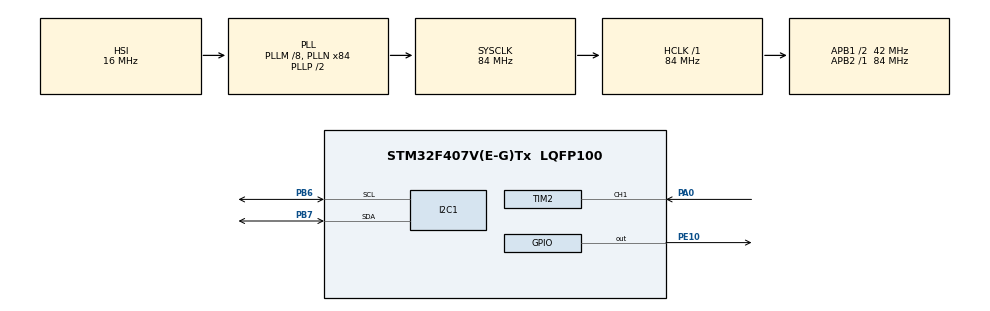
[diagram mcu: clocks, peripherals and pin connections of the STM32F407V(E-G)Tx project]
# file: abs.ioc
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Mcu.Family=STM32F4
Mcu.Name=STM32F407V(E-G)Tx
Mcu.Package=LQFP100
NVIC.I2C1_ER_IRQn=true\:0\:0\:false\:false\:true\:true\:true\:true
NVIC.I2C1_EV_IRQn=true\:0\:0\:false\:false\:true\:true\:true\:true
NVIC.PriorityGroup=NVIC_PRIORITYGROUP_4
NVIC.TIM2_IRQn=true\:0\:0\:false\:false\:true\:true\:true\:true
PA0-WKUP.Signal=S_TIM2_CH1_ETR
PB6.Mode=I2C
PB6.Signal=I2C1_SCL
PB7.Mode=I2C
PB7.Signal=I2C1_SDA
PE10.Signal=GPIO_Output
ProjectManager.HeapSize=0x200
ProjectManager.StackSize=0x400
ProjectManager.TargetToolchain=STM32CubeIDE
RCC.48MHZClocksFreq_Value=42000000
RCC.AHBFreq_Value=84000000
RCC.APB1CLKDivider=RCC_HCLK_DIV2
RCC.APB1Freq_Value=42000000
RCC.APB1TimFreq_Value=84000000
RCC.APB2Freq_Value=84000000
RCC.APB2TimFreq_Value=84000000
RCC.CortexFreq_Value=84000000
RCC.HCLKFreq_Value=84000000
RCC.HSE_VALUE=25000000
RCC.HSI_VALUE=16000000
RCC.LSE_VALUE=32768
RCC.PLLM=8
RCC.PLLN=84
RCC.SYSCLKFreq_VALUE=84000000
RCC.SYSCLKSource=RCC_SYSCLKSOURCE_PLLCLK
RCC.VCOOutputFreq_Value=168000000
SH.S_TIM2_CH1_ETR.0=TIM2_CH1,Input_Capture1_from_TI1
TIM2.Channel-Input_Capture1_from_TI1=TIM_CHANNEL_1
TIM2.Period=65535
TIM2.Prescaler=83
VP_TIM2_VS_ClockSourceINT.Mode=Internal
board=custom

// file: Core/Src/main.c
/* USER CODE BEGIN Header */
/**
  ******************************************************************************
  * @file           : main.c
  * @brief          : Main program body
  ******************************************************************************
  * @attention
  *
  * Copyright (c) 2025 STMicroelectronics.
  * All rights reserved.
  *
  * This software is licensed under terms that can be found in the LICENSE file
  * in the root directory of this software component.
  * If no LICENSE file comes with this software, it is provided AS-IS.
  *
  ******************************************************************************
  */
/* USER CODE END Header */
#include "main.h"
#include <string.h>
#include <stdio.h>
#include<lcd_i2c.h>

I2C_HandleTypeDef hi2c1;

TIM_HandleTypeDef htim2;

/* USER CODE BEGIN PV */
#define SLAVE_ADDRESS_LCD 0x4E

/* USER CODE END PV */

void SystemClock_Config(void);
static void MX_GPIO_Init(void);
static void MX_I2C1_Init(void);
static void MX_TIM2_Init(void);
/* USER CODE BEGIN PFP */

/* USER CODE END PV */

void SystemClock_Config(void);
static void MX_GPIO_Init(void);
static void MX_I2C1_Init(void);
static void MX_TIM2_Init(void);
/* USER CODE BEGIN PFP */

uint32_t ic_val1 = 0;
uint32_t ic_val2 = 0;
uint8_t is_first_captured = 0;
uint32_t difference = 0;
float distance = 0;

// ====== LCD Functions ======
void lcd_send_cmd(char cmd);
void lcd_send_data(char data);
void lcd_init(void);
void lcd_send_string(char *str);
void lcd_put_cur(int row, int col);

// ====== Ultrasonic Functions ======
void Ultrasonic_Trigger(void) {
    HAL_GPIO_WritePin(GPIOE, GPIO_PIN_10, GPIO_PIN_SET);
    HAL_Delay(0.1); // 10 us pulse
    HAL_GPIO_WritePin(GPIOE, GPIO_PIN_10, GPIO_PIN_RESET);
}

void HAL_TIM_IC_CaptureCallback(TIM_HandleTypeDef *htim) {
    if (htim->Channel == HAL_TIM_ACTIVE_CHANNEL_1) {
        if (is_first_captured==0) {
            ic_val1 = HAL_TIM_ReadCapturedValue(htim, TIM_CHANNEL_1);
            is_first_captured = 1;
            __HAL_TIM_SET_CAPTUREPOLARITY(htim, TIM_CHANNEL_1, TIM_INPUTCHANNELPOLARITY_FALLING);
        }
        else if (is_first_captured==1) {
            ic_val2 = HAL_TIM_ReadCapturedValue(htim, TIM_CHANNEL_1);
            if (ic_val2 > ic_val1) difference = ic_val2-ic_val1;
            else difference = (0xffff-ic_val1)+ic_val2;

            distance = (difference * 0.0343)/2; // in cm
            is_first_captured = 0;
            __HAL_TIM_SET_CAPTUREPOLARITY(htim, TIM_CHANNEL_1, TIM_INPUTCHANNELPOLARITY_RISING);
            __HAL_TIM_DISABLE_IT(htim, TIM_IT_CC1);
        }
    }
}

float Get_Distance(void) {
    Ultrasonic_Trigger();
    __HAL_TIM_ENABLE_IT(&htim2, TIM_IT_CC1);
    HAL_Delay(100);
    return distance;
}

// ====== Main ======
int main(void) {
    HAL_Init();
    SystemClock_Config();
    MX_GPIO_Init();
    MX_I2C1_Init();
    MX_TIM2_Init();

    HAL_TIM_IC_Start_IT(&htim2, TIM_CHANNEL_1);
    lcd_init();

    char buffer[50];
    while (1) {
        float dist = Get_Distance();
        int dist_int = (int)(dist + 0.5); // rounded integer cm

        sprintf(buffer, "Distance=%d ", dist_int);

        lcd_put_cur(0,0);
        lcd_send_string("Ultrasonic:");
        lcd_put_cur(1,0);
        lcd_send_string(buffer);

        HAL_Delay(100);
    }
}
//int main(void)
//{
//
//  /* USER CODE BEGIN 1 */
//
//  /* USER CODE END 1 */
//
//  /* MCU Configuration--------------------------------------------------------*/
//
//  /* Reset of all peripherals, Initializes the Flash interface and the Systick. */
//  HAL_Init();
//
//  /* USER CODE BEGIN Init */
//
//  /* USER CODE END Init */
//
//  /* Configure the system clock */
//  SystemClock_Config();
//
//  /* USER CODE BEGIN SysInit */
//
//  /* USER CODE END SysInit */
//
//  /* Initialize all configured peripherals */
//  MX_GPIO_Init();
//  MX_I2C1_Init();
//  MX_TIM2_Init();
//  /* USER CODE BEGIN 2 */
//
//  /* USER CODE END 2 */
//
//  /* Infinite loop */
//  /* USER CODE BEGIN WHILE */
//  while (1)
//  {
//    /* USER CODE END WHILE */
//
//    /* USER CODE BEGIN 3 */
//  }
//  /* USER CODE END 3 */
//}

void SystemClock_Config(void)
{
  RCC_OscInitTypeDef RCC_OscInitStruct = {0};
  RCC_ClkInitTypeDef RCC_ClkInitStruct = {0};

  /** Configure the main internal regulator output voltage
  */
  __HAL_RCC_PWR_CLK_ENABLE();
  __HAL_PWR_VOLTAGESCALING_CONFIG(PWR_REGULATOR_VOLTAGE_SCALE1);

  /** Initializes the RCC Oscillators according to the specified parameters
  * in the RCC_OscInitTypeDef structure.
  */
  RCC_OscInitStruct.OscillatorType = RCC_OSCILLATORTYPE_HSI;
  RCC_OscInitStruct.HSIState = RCC_HSI_ON;
  RCC_OscInitStruct.HSICalibrationValue = RCC_HSICALIBRATION_DEFAULT;
  RCC_OscInitStruct.PLL.PLLState = RCC_PLL_ON;
  RCC_OscInitStruct.PLL.PLLSource = RCC_PLLSOURCE_HSI;
  RCC_OscInitStruct.PLL.PLLM = 8;
  RCC_OscInitStruct.PLL.PLLN = 84;
  RCC_OscInitStruct.PLL.PLLP = RCC_PLLP_DIV2;
  RCC_OscInitStruct.PLL.PLLQ = 4;
  if (HAL_RCC_OscConfig(&RCC_OscInitStruct) != HAL_OK)
  {
    Error_Handler();
  }

  /** Initializes the CPU, AHB and APB buses clocks
  */
  RCC_ClkInitStruct.ClockType = RCC_CLOCKTYPE_HCLK|RCC_CLOCKTYPE_SYSCLK
                              |RCC_CLOCKTYPE_PCLK1|RCC_CLOCKTYPE_PCLK2;
  RCC_ClkInitStruct.SYSCLKSource = RCC_SYSCLKSOURCE_PLLCLK;
  RCC_ClkInitStruct.AHBCLKDivider = RCC_SYSCLK_DIV1;
  RCC_ClkInitStruct.APB1CLKDivider = RCC_HCLK_DIV2;
  RCC_ClkInitStruct.APB2CLKDivider = RCC_HCLK_DIV1;

  if (HAL_RCC_ClockConfig(&RCC_ClkInitStruct, FLASH_LATENCY_2) != HAL_OK)
  {
    Error_Handler();
  }
}

static void MX_I2C1_Init(void)
{

  hi2c1.Instance = I2C1;
  hi2c1.Init.ClockSpeed = 100000;
  hi2c1.Init.DutyCycle = I2C_DUTYCYCLE_2;
  hi2c1.Init.OwnAddress1 = 0;
  hi2c1.Init.AddressingMode = I2C_ADDRESSINGMODE_7BIT;
  hi2c1.Init.DualAddressMode = I2C_DUALADDRESS_DISABLE;
  hi2c1.Init.OwnAddress2 = 0;
  hi2c1.Init.GeneralCallMode = I2C_GENERALCALL_DISABLE;
  hi2c1.Init.NoStretchMode = I2C_NOSTRETCH_DISABLE;
  if (HAL_I2C_Init(&hi2c1) != HAL_OK)
  {
    Error_Handler();
  }

}

static void MX_TIM2_Init(void)
{

  TIM_ClockConfigTypeDef sClockSourceConfig = {0};
  TIM_MasterConfigTypeDef sMasterConfig = {0};
  TIM_IC_InitTypeDef sConfigIC = {0};

  htim2.Instance = TIM2;
  htim2.Init.Prescaler = 83;
  htim2.Init.CounterMode = TIM_COUNTERMODE_UP;
  htim2.Init.Period = 4294967295;
  htim2.Init.ClockDivision = TIM_CLOCKDIVISION_DIV1;
  htim2.Init.AutoReloadPreload = TIM_AUTORELOAD_PRELOAD_DISABLE;
  if (HAL_TIM_Base_Init(&htim2) != HAL_OK)
  {
    Error_Handler();
  }
  sClockSourceConfig.ClockSource = TIM_CLOCKSOURCE_INTERNAL;
  if (HAL_TIM_ConfigClockSource(&htim2, &sClockSourceConfig) != HAL_OK)
  {
    Error_Handler();
  }
  if (HAL_TIM_IC_Init(&htim2) != HAL_OK)
  {
    Error_Handler();
  }
  sMasterConfig.MasterOutputTrigger = TIM_TRGO_RESET;
  sMasterConfig.MasterSlaveMode = TIM_MASTERSLAVEMODE_DISABLE;
  if (HAL_TIMEx_MasterConfigSynchronization(&htim2, &sMasterConfig) != HAL_OK)
  {
    Error_Handler();
  }
  sConfigIC.ICPolarity = TIM_INPUTCHANNELPOLARITY_RISING;
  sConfigIC.ICSelection = TIM_ICSELECTION_DIRECTTI;
  sConfigIC.ICPrescaler = TIM_ICPSC_DIV1;
  sConfigIC.ICFilter = 0;
  if (HAL_TIM_IC_ConfigChannel(&htim2, &sConfigIC, TIM_CHANNEL_1) != HAL_OK)
  {
    Error_Handler();
  }

}

static void MX_GPIO_Init(void)
{
  GPIO_InitTypeDef GPIO_InitStruct = {0};

  /* GPIO Ports Clock Enable */
  __HAL_RCC_GPIOA_CLK_ENABLE();
  __HAL_RCC_GPIOE_CLK_ENABLE();
  __HAL_RCC_GPIOB_CLK_ENABLE();

  /*Configure GPIO pin Output Level */
  HAL_GPIO_WritePin(GPIOE, GPIO_PIN_10, GPIO_PIN_RESET);

  /*Configure GPIO pin : PE10 */
  GPIO_InitStruct.Pin = GPIO_PIN_10;
  GPIO_InitStruct.Mode = GPIO_MODE_OUTPUT_PP;
  GPIO_InitStruct.Pull = GPIO_NOPULL;
  GPIO_InitStruct.Speed = GPIO_SPEED_FREQ_LOW;
  HAL_GPIO_Init(GPIOE, &GPIO_InitStruct);

}

void Error_Handler(void)
{
  __disable_irq();
  while (1)
  {
  }
}
